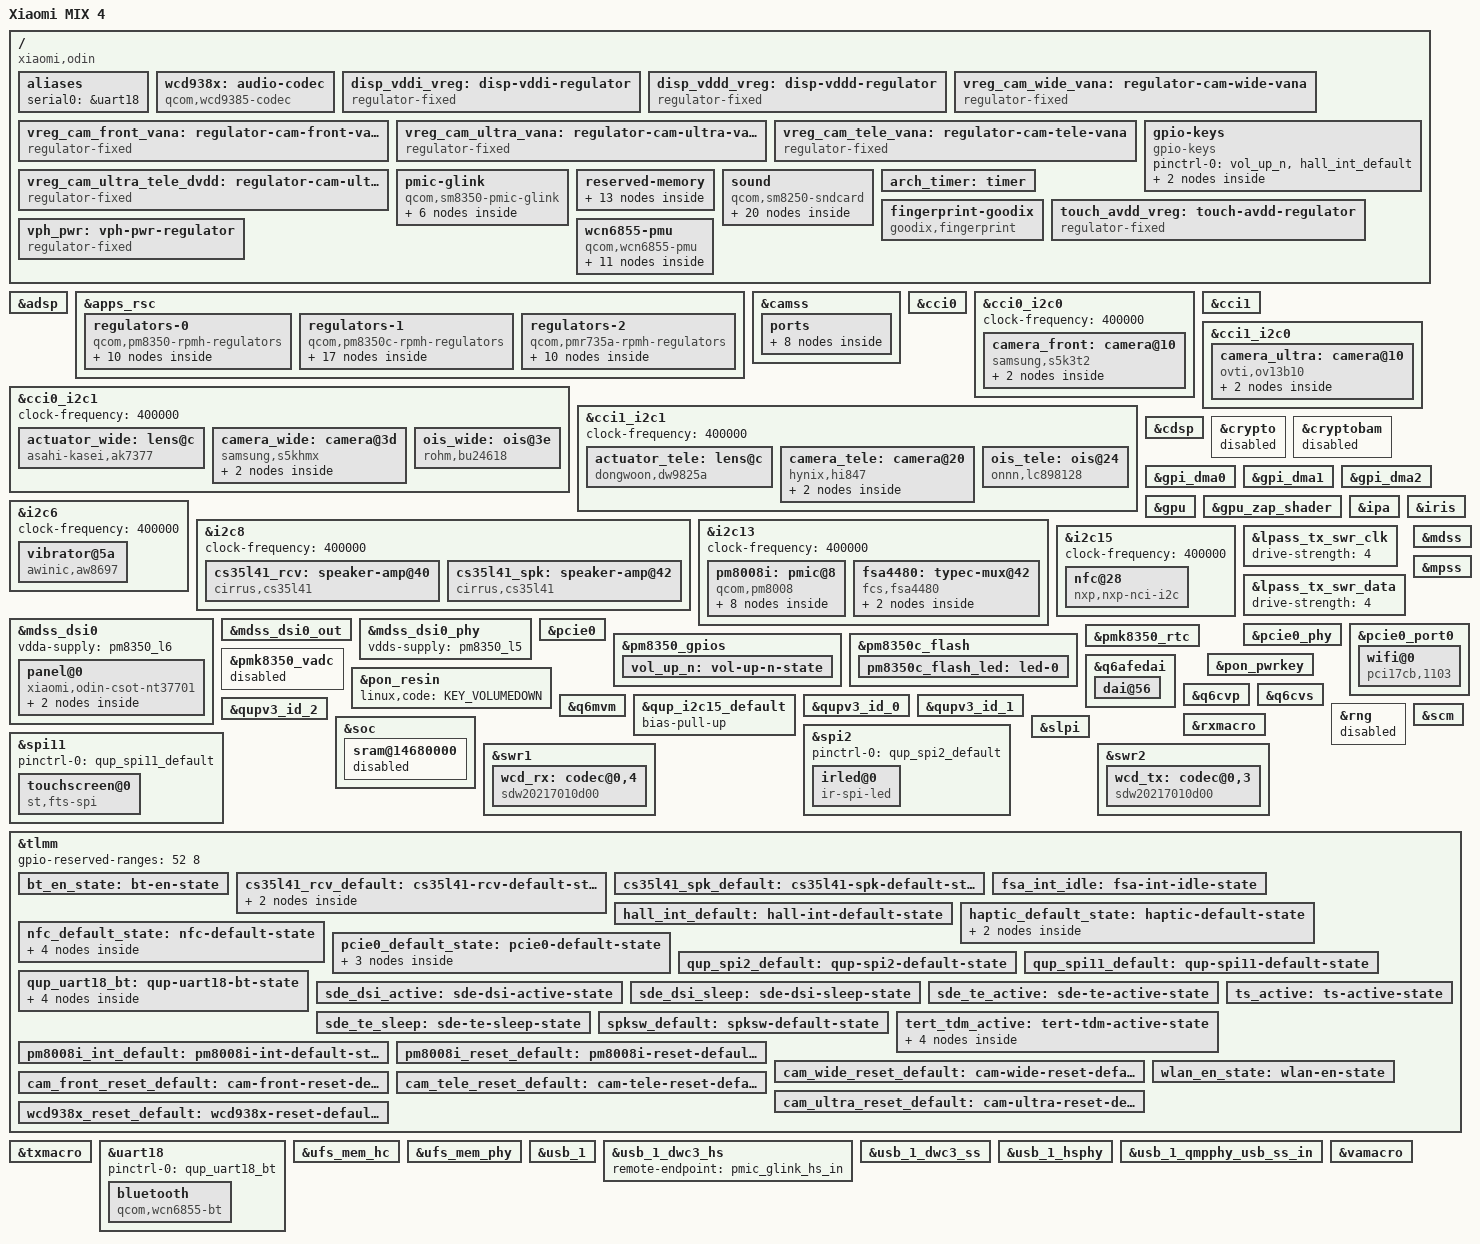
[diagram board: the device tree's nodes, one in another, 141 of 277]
// SPDX-License-Identifier: BSD-3-Clause

/dts-v1/;

#include <dt-bindings/clock/qcom,rpmh.h>
#include <dt-bindings/firmware/qcom,scm.h>
#include <dt-bindings/gpio/gpio.h>
#include <dt-bindings/input/input.h>
#include <dt-bindings/interconnect/qcom,icc.h>
#include <dt-bindings/interconnect/qcom,sm8350.h>
#include <dt-bindings/leds/common.h>
#include <dt-bindings/media/video-interfaces.h>
#include <dt-bindings/pinctrl/qcom,pmic-gpio.h>
#include <dt-bindings/power/qcom,rpmhpd.h>
#include <dt-bindings/regulator/qcom,rpmh-regulator.h>
#include <dt-bindings/sound/qcom,q6afe.h>
#include <dt-bindings/sound/qcom,q6asm.h>
#include <dt-bindings/sound/qcom,q6voice.h>
#include "sm8350.dtsi"
#include "pm8350.dtsi"
#include "pm8350b.dtsi"
#include "pm8350c.dtsi"
#include "pmk8350.dtsi"
#include "pmr735a.dtsi"

/delete-node/ &xbl_aop_mem;
/delete-node/ &pil_adsp_mem;
/delete-node/ &pil_slpi_mem;
/delete-node/ &pil_cdsp_mem;
/delete-node/ &pil_ipa_fw_mem;
/delete-node/ &pil_ipa_gsi_mem;
/delete-node/ &pil_gpu_mem;
/delete-node/ &pil_spss_mem;
/delete-node/ &pil_modem_mem;
/delete-node/ &rmtfs_mem;
/delete-node/ &hyp_reserved_mem;
/delete-node/ &pil_trustedvm_mem;
/delete-node/ &qrtr_shbuf;
/delete-node/ &chan0_shbuf;
/delete-node/ &chan1_shbuf;
/delete-node/ &removed_mem;

/ {
	model = "Xiaomi MIX 4";
	compatible = "xiaomi,odin", "qcom,sm8350";
	chassis-type = "handset";

	qcom,msm-id = <0x19f 0x20001 0x1c8 0x20001 0x1f5 0x20001>;
	qcom,board-id = <0 0>;

	aliases {
		serial0 = &uart18;
	};

	wcd938x: audio-codec {
		compatible = "qcom,wcd9385-codec";
		pinctrl-names = "default";
		pinctrl-0 = <&wcd938x_reset_default>;
		reset-gpios = <&tlmm 88 GPIO_ACTIVE_LOW>;

		vdd-rxtx-supply = <&pm8350_s10>;
		vdd-io-supply = <&pm8350_s10>;
		vdd-buck-supply = <&pm8350_s10>;
		vdd-mic-bias-supply = <&vreg_bob>;

		qcom,micbias1-microvolt = <2750000>;
		qcom,micbias2-microvolt = <2750000>;
		qcom,micbias3-microvolt = <2750000>;
		qcom,micbias4-microvolt = <2750000>;

		qcom,hphl-jack-type-normally-closed;
		qcom,ground-jack-type-normally-closed;
		qcom,mbhc-buttons-vthreshold-microvolt = <75000 150000 237000 500000
							  500000 500000 500000 500000>;
		qcom,mbhc-headset-vthreshold-microvolt = <1700000>;
		qcom,mbhc-headphone-vthreshold-microvolt = <50000>;

		qcom,rx-device = <&wcd_rx>;
		qcom,tx-device = <&wcd_tx>;

		#sound-dai-cells = <1>;
	};

	disp_vddi_vreg: disp-vddi-regulator {
		compatible = "regulator-fixed";
		regulator-name = "display_prim_vddi";
		gpio = <&tlmm 42 GPIO_ACTIVE_HIGH>;
		startup-delay-us = <2000>;
		enable-active-high;
		regulator-boot-on;
	};

	disp_vddd_vreg: disp-vddd-regulator {
		compatible = "regulator-fixed";
		regulator-name = "display_prim_vddd";
		gpio = <&tlmm 83 GPIO_ACTIVE_HIGH>;
		startup-delay-us = <2000>;
		enable-active-high;
		regulator-boot-on;
	};

	vreg_cam_wide_vana: regulator-cam-wide-vana {
		compatible = "regulator-fixed";
		regulator-name = "vreg_cam_wide_vana";
		regulator-min-microvolt = <2800000>;
		regulator-max-microvolt = <2800000>;
		startup-delay-us = <135>;
		off-on-delay-us = <20000>;
		enable-active-high;
		gpio = <&tlmm 6 GPIO_ACTIVE_HIGH>;
		vin-supply = <&vreg_bob>;
	};

	vreg_cam_front_vana: regulator-cam-front-vana {
		compatible = "regulator-fixed";
		regulator-name = "vreg_cam_front_vana";
		regulator-min-microvolt = <2800000>;
		regulator-max-microvolt = <2800000>;
		startup-delay-us = <135>;
		off-on-delay-us = <20000>;
		enable-active-high;
		gpio = <&tlmm 93 GPIO_ACTIVE_HIGH>;
		vin-supply = <&vreg_bob>;
	};

	vreg_cam_ultra_vana: regulator-cam-ultra-vana {
		compatible = "regulator-fixed";
		regulator-name = "vreg_cam_ultra_vana";
		regulator-min-microvolt = <2800000>;
		regulator-max-microvolt = <2800000>;
		startup-delay-us = <135>;
		off-on-delay-us = <20000>;
		enable-active-high;
		gpio = <&tlmm 66 GPIO_ACTIVE_HIGH>;
		vin-supply = <&vreg_bob>;
	};

	vreg_cam_tele_vana: regulator-cam-tele-vana {
		compatible = "regulator-fixed";
		regulator-name = "vreg_cam_tele_vana";
		regulator-min-microvolt = <2800000>;
		regulator-max-microvolt = <2800000>;
		startup-delay-us = <135>;
		off-on-delay-us = <20000>;
		enable-active-high;
		gpio = <&tlmm 34 GPIO_ACTIVE_HIGH>;
		vin-supply = <&vreg_bob>;
	};

	vreg_cam_ultra_tele_dvdd: regulator-cam-ultra-tele-dvdd {
		compatible = "regulator-fixed";
		regulator-name = "vreg_cam_ultra_tele_dvdd";
		regulator-min-microvolt = <1200000>;
		regulator-max-microvolt = <1200000>;
		startup-delay-us = <135>;
		off-on-delay-us = <20000>;
		enable-active-high;
		gpio = <&tlmm 74 GPIO_ACTIVE_HIGH>;
	};

	gpio-keys {
		compatible = "gpio-keys";

		pinctrl-names = "default";
		pinctrl-0 = <&vol_up_n &hall_int_default>;

		key-vol-up {
			label = "Volume Up";
			linux,code = <KEY_VOLUMEUP>;
			gpios = <&pm8350_gpios 6 GPIO_ACTIVE_LOW>;
			debounce-interval = <15>;
			linux,can-disable;
			wakeup-source;
		};

		switch-hall {
			label = "Hall Sensor";
			linux,input-type = <EV_SW>;
			linux,code = <SW_LID>;
			gpios = <&tlmm 80 GPIO_ACTIVE_LOW>;
			debounce-interval = <15>;
			wakeup-source;
		};
	};

	pmic-glink {
		compatible = "qcom,sm8350-pmic-glink", "qcom,pmic-glink";
		#address-cells = <1>;
		#size-cells = <0>;

		connector@0 {
			compatible = "usb-c-connector";
			reg = <0>;
			power-role = "dual";
			data-role = "dual";

			ports {
				#address-cells = <1>;
				#size-cells = <0>;

				port@0 {
					reg = <0>;

					pmic_glink_hs_in: endpoint {
						remote-endpoint = <&usb_1_dwc3_hs>;
					};
				};

				port@2 {
					reg = <2>;

					pmic_glink_sbu: endpoint {
						remote-endpoint = <&fsa4480_sbu_mux>;
					};
				};
			};
		};
	};

	reserved-memory {
		xbl_aop_mem: memory@80600000 {
			reg = <0x0 0x80600000 0x0 0x260000>;
			no-map;
		};

		pil_adsp_mem: memory@86100000 {
			reg = <0x0 0x86100000 0x0 0x3900000>;
			no-map;
		};

		pil_slpi_mem: memory@89a00000 {
			reg = <0x0 0x89a00000 0x0 0x2f00000>;
			no-map;
		};

		pil_cdsp_mem: memory@8c900000 {
			reg = <0x0 0x8c900000 0x0 0x1e00000>;
			no-map;
		};

		pil_ipa_fw_mem: memory@8e700000 {
			reg = <0x0 0x8e700000 0x0 0x10000>;
			no-map;
		};

		pil_ipa_gsi_mem: memory@8e710000 {
			reg = <0x0 0x8e710000 0x0 0xa000>;
			no-map;
		};

		pil_gpu_mem: memory@8e71a000 {
			reg = <0x0 0x8e71a000 0x0 0x2000>;
			no-map;
		};

		pil_spss_mem: memory@8e800000 {
			reg = <0x0 0x8e800000 0x0 0x100000>;
			no-map;
		};

		pil_modem_mem: memory@8f000000 {
			reg = <0x0 0x8f000000 0x0 0x10000000>;
			no-map;
		};

		rmtfs_mem: memory@9f000000 {
			compatible = "qcom,rmtfs-mem";
			reg = <0x0 0x9f000000 0x0 0x300000>;
			no-map;

			qcom,client-id = <1>;
			qcom,vmid = <QCOM_SCM_VMID_MSS_MSA>;
		};

		removed_mem: memory@d8800000 {
			reg = <0x0 0xd8800000 0x0 0xa000000>;
			no-map;
		};

		cont_splash_mem: memory@ea600000 {
			reg = <0x0 0xea600000 0x0 0x2300000>;
			no-map;
		};

		dfps_data_mem: memory@ec900000 {
			reg = <0x0 0xec900000 0x0 0x100000>;
			no-map;
		};
	};

	sound {
		compatible = "qcom,sm8250-sndcard";
		model = "Xiaomi MIX 4";
		pinctrl-names = "default";
		pinctrl-0 = <&tert_tdm_active &spksw_default>;

		audio-routing =
			"IN1_HPHL", "HPHL_OUT",
			"IN2_HPHR", "HPHR_OUT",
			"AMIC1", "MIC BIAS1",
			"AMIC2", "MIC BIAS2",
			"AMIC3", "MIC BIAS3",
			"AMIC5", "MIC BIAS4",
			"TX SWR_INPUT0", "ADC1_OUTPUT",
			"TX SWR_INPUT1", "ADC2_OUTPUT",
			"TX SWR_INPUT4", "ADC3_OUTPUT",
			"TX SWR_INPUT5", "ADC4_OUTPUT";

		mm1-dai-link {
			link-name = "MultiMedia1";

			cpu {
				sound-dai = <&q6asmdai MSM_FRONTEND_DAI_MULTIMEDIA1>;
			};
		};

		mm2-dai-link {
			link-name = "MultiMedia2";

			cpu {
				sound-dai = <&q6asmdai MSM_FRONTEND_DAI_MULTIMEDIA2>;
			};
		};

		mm3-dai-link {
			link-name = "MultiMedia3";

			cpu {
				sound-dai = <&q6asmdai MSM_FRONTEND_DAI_MULTIMEDIA3>;
			};
		};

		voicemmode1-dai-link {
			link-name = "VoiceMMode1";

			cpu {
				sound-dai = <&q6voicedai VOICEMMODE1>;
			};
		};

		speaker-dai-link {
			link-name = "Tertiary TDM Playback";

			cpu {
				sound-dai = <&q6afedai TERTIARY_TDM_RX_0>;
			};

			platform {
				sound-dai = <&q6routing>;
			};

			codec {
				sound-dai = <&cs35l41_rcv 0>, <&cs35l41_spk 0>;
			};
		};

		wcd-playback-dai-link {
			link-name = "WCD Playback";

			cpu {
				sound-dai = <&q6afedai RX_CODEC_DMA_RX_0>;
			};

			platform {
				sound-dai = <&q6routing>;
			};

			codec {
				sound-dai = <&wcd938x 0>, <&swr1 0>, <&rxmacro 0>;
			};
		};

		wcd-capture-dai-link {
			link-name = "WCD Capture";

			cpu {
				sound-dai = <&q6afedai TX_CODEC_DMA_TX_3>;
			};

			platform {
				sound-dai = <&q6routing>;
			};

			codec {
				sound-dai = <&wcd938x 1>, <&swr2 0>, <&txmacro 0>;
			};
		};
	};

	/* The arch_timer label is required by Gunyah/ABL to apply HypOverlay */
	arch_timer: timer { };

	fingerprint-goodix {
		compatible = "goodix,fingerprint";
		l11c-vdd-supply = <&pm8350c_l11>;
		reset-gpios = <&tlmm 39 GPIO_ACTIVE_LOW>;
		irq-gpios = <&tlmm 38 GPIO_ACTIVE_HIGH>;
	};

	touch_avdd_vreg: touch-avdd-regulator {
		compatible = "regulator-fixed";
		regulator-name = "touch_avdd";
		gpio = <&tlmm 132 GPIO_ACTIVE_HIGH>;
		enable-active-high;
	};

	vph_pwr: vph-pwr-regulator {
		compatible = "regulator-fixed";
		regulator-name = "vph_pwr";
		regulator-min-microvolt = <3700000>;
		regulator-max-microvolt = <3700000>;

		regulator-always-on;
		regulator-boot-on;
	};

	wcn6855-pmu {
		compatible = "qcom,wcn6855-pmu";

		pinctrl-names = "default";
		pinctrl-0 = <&bt_en_state>, <&wlan_en_state>;

		wlan-enable-gpios = <&tlmm 64 GPIO_ACTIVE_HIGH>;
		bt-enable-gpios = <&tlmm 65 GPIO_ACTIVE_HIGH>;
		swctrl-gpios = <&tlmm 153 GPIO_ACTIVE_HIGH>;

		vddio-supply = <&pm8350_s10>;
		vddaon-supply = <&pm8350_s11>;
		vddpmu-supply = <&pm8350_s12>;
		vddpmumx-supply = <&pmr735a_s2>;
		vddpmucx-supply = <&pm8350_s11>;
		vddrfa0p95-supply = <&pm8350_s11>;
		vddrfa1p3-supply = <&pm8350_s12>;
		vddrfa1p9-supply = <&pm8350c_s1>;
		vddpcie1p3-supply = <&pm8350_s12>;
		vddpcie1p9-supply = <&pm8350c_s1>;

		regulators {
			vreg_pmu_rfa_cmn: ldo0 {
				regulator-name = "vreg_pmu_rfa_cmn";
			};

			vreg_pmu_aon_0p8: ldo1 {
				regulator-name = "vreg_pmu_aon_0p8";
			};

			vreg_pmu_wlcx_0p8: ldo2 {
				regulator-name = "vreg_pmu_wlcx_0p8";
			};

			vreg_pmu_wlmx_0p8: ldo3 {
				regulator-name = "vreg_pmu_wlmx_0p8";
			};

			vreg_pmu_btcmx_0p8: ldo4 {
				regulator-name = "vreg_pmu_btcmx_0p8";
			};

			vreg_pmu_pcie_1p8: ldo5 {
				regulator-name = "vreg_pmu_pcie_1p8";
			};

			vreg_pmu_pcie_0p9: ldo6 {
				regulator-name = "vreg_pmu_pcie_0p9";
			};

			vreg_pmu_rfa_0p8: ldo7 {
				regulator-name = "vreg_pmu_rfa_0p8";
			};

			vreg_pmu_rfa_1p2: ldo8 {
				regulator-name = "vreg_pmu_rfa_1p2";
			};

			vreg_pmu_rfa_1p7: ldo9 {
				regulator-name = "vreg_pmu_rfa_1p7";
			};
		};
	};
};

&adsp {
	firmware-name = "qcom/sm8350/xiaomi/odin/adsp.mbn";
	status = "okay";
};

&apps_rsc {
	regulators-0 {
		compatible = "qcom,pm8350-rpmh-regulators";
		qcom,pmic-id = "b";

		vdd-s1-supply = <&vph_pwr>;
		vdd-s2-supply = <&vph_pwr>;
		vdd-s3-supply = <&vph_pwr>;
		vdd-s4-supply = <&vph_pwr>;
		vdd-s5-supply = <&vph_pwr>;
		vdd-s6-supply = <&vph_pwr>;
		vdd-s7-supply = <&vph_pwr>;
		vdd-s8-supply = <&vph_pwr>;
		vdd-s9-supply = <&vph_pwr>;
		vdd-s10-supply = <&vph_pwr>;
		vdd-s11-supply = <&vph_pwr>;
		vdd-s12-supply = <&vph_pwr>;

		vdd-l1-l4-supply = <&pm8350_s11>;
		vdd-l2-l7-supply = <&vreg_bob>;
		vdd-l3-l5-supply = <&pm8350_s11>;
		vdd-l6-l9-l10-supply = <&pm8350_s12>;

		pm8350_s10: smps10 {
			regulator-name = "pm8350_s10";
			regulator-min-microvolt = <1800000>;
			regulator-max-microvolt = <1800000>;
			regulator-initial-mode = <RPMH_REGULATOR_MODE_HPM>;
		};

		pm8350_s11: smps11 {
			regulator-name = "pm8350_s11";
			regulator-min-microvolt = <1008000>;
			regulator-max-microvolt = <1008000>;
			regulator-initial-mode = <RPMH_REGULATOR_MODE_HPM>;
		};

		pm8350_s12: smps12 {
			regulator-name = "pm8350_s12";
			regulator-min-microvolt = <1352000>;
			regulator-max-microvolt = <1352000>;
			regulator-initial-mode = <RPMH_REGULATOR_MODE_HPM>;
		};

		pm8350_l1: ldo1 {
			regulator-name = "pm8350_l1";
			regulator-min-microvolt = <912000>;
			regulator-max-microvolt = <920000>;
			regulator-initial-mode = <RPMH_REGULATOR_MODE_HPM>;
		};

		pm8350_l2: ldo2 {
			regulator-name = "pm8350_l2";
			regulator-min-microvolt = <3072000>;
			regulator-max-microvolt = <3072000>;
			regulator-initial-mode = <RPMH_REGULATOR_MODE_HPM>;
		};

		pm8350_l3: ldo3 {
			regulator-name = "pm8350_l3";
			regulator-min-microvolt = <904000>;
			regulator-max-microvolt = <904000>;
			regulator-initial-mode = <RPMH_REGULATOR_MODE_HPM>;
		};

		pm8350_l5: ldo5 {
			regulator-name = "pm8350_l5";
			regulator-min-microvolt = <880000>;
			regulator-max-microvolt = <888000>;
			regulator-initial-mode = <RPMH_REGULATOR_MODE_HPM>;
			regulator-allow-set-load;
			regulator-allowed-modes = <RPMH_REGULATOR_MODE_HPM>;
		};

		pm8350_l6: ldo6 {
			regulator-name = "pm8350_l6";
			regulator-min-microvolt = <1200000>;
			regulator-max-microvolt = <1208000>;
			regulator-initial-mode = <RPMH_REGULATOR_MODE_HPM>;
			regulator-allow-set-load;
			regulator-allowed-modes = <RPMH_REGULATOR_MODE_HPM>;
		};

		pm8350_l7: ldo7 {
			regulator-name = "pm8350_l7";
			regulator-min-microvolt = <2400000>;
			regulator-max-microvolt = <3008000>;
			regulator-initial-mode = <RPMH_REGULATOR_MODE_HPM>;
			regulator-allow-set-load;
			regulator-allowed-modes = <RPMH_REGULATOR_MODE_LPM
						   RPMH_REGULATOR_MODE_HPM>;
		};

		pm8350_l9: ldo9 {
			regulator-name = "pm8350_l9";
			regulator-min-microvolt = <1200000>;
			regulator-max-microvolt = <1200000>;
			regulator-initial-mode = <RPMH_REGULATOR_MODE_HPM>;
			regulator-allow-set-load;
			regulator-allowed-modes = <RPMH_REGULATOR_MODE_LPM
						   RPMH_REGULATOR_MODE_HPM>;
		};
	};

	regulators-1 {
		compatible = "qcom,pm8350c-rpmh-regulators";
		qcom,pmic-id = "c";

		vdd-s1-supply = <&vph_pwr>;
		vdd-s2-supply = <&vph_pwr>;
		vdd-s3-supply = <&vph_pwr>;
		vdd-s4-supply = <&vph_pwr>;
		vdd-s5-supply = <&vph_pwr>;
		vdd-s6-supply = <&vph_pwr>;
		vdd-s7-supply = <&vph_pwr>;
		vdd-s8-supply = <&vph_pwr>;
		vdd-s9-supply = <&vph_pwr>;
		vdd-s10-supply = <&vph_pwr>;

		vdd-l1-l12-supply = <&pm8350c_s1>;
		vdd-l2-l8-supply = <&pm8350c_s1>;
		vdd-l3-l4-l5-l7-l13-supply = <&vreg_bob>;
		vdd-l6-l9-l11-supply = <&vreg_bob>;
		vdd-l10-supply = <&pm8350_s12>;

		vdd-bob-supply = <&vph_pwr>;

		pm8350c_s1: smps1 {
			regulator-name = "pm8350c_s1";
			regulator-min-microvolt = <1904000>;
			regulator-max-microvolt = <1904000>;
			regulator-initial-mode = <RPMH_REGULATOR_MODE_HPM>;
		};

		pm8350c_s3: smps3 {
			regulator-name = "pm8350c_s3";
			regulator-min-microvolt = <300000>;
			regulator-max-microvolt = <704000>;
			regulator-initial-mode = <RPMH_REGULATOR_MODE_HPM>;
		};

		pm8350c_s10: smps10 {
			regulator-name = "pm8350c_s10";
			regulator-min-microvolt = <1048000>;
			regulator-max-microvolt = <1128000>;
			regulator-initial-mode = <RPMH_REGULATOR_MODE_HPM>;
		};

		pm8350c_l1: ldo1 {
			regulator-name = "pm8350c_l1";
			regulator-min-microvolt = <1800000>;
			regulator-max-microvolt = <1800000>;
			regulator-initial-mode = <RPMH_REGULATOR_MODE_HPM>;
		};

		pm8350c_l2: ldo2 {
			regulator-name = "pm8350c_l2";
			regulator-min-microvolt = <1800000>;
			regulator-max-microvolt = <1800000>;
			regulator-initial-mode = <RPMH_REGULATOR_MODE_HPM>;
		};

		pm8350c_l3: ldo3 {
			regulator-name = "pm8350c_l3";
			regulator-min-microvolt = <3008000>;
			regulator-max-microvolt = <3008000>;
			regulator-initial-mode = <RPMH_REGULATOR_MODE_HPM>;
		};

		pm8350c_l4: ldo4 {
			regulator-name = "pm8350c_l4";
			regulator-min-microvolt = <1704000>;
			regulator-max-microvolt = <3000000>;
			regulator-initial-mode = <RPMH_REGULATOR_MODE_HPM>;
		};

		pm8350c_l5: ldo5 {
			regulator-name = "pm8350c_l5";
			regulator-min-microvolt = <1704000>;
			regulator-max-microvolt = <3000000>;
			regulator-initial-mode = <RPMH_REGULATOR_MODE_HPM>;
		};

		pm8350c_l6: ldo6 {
			regulator-name = "pm8350c_l6";
			regulator-min-microvolt = <1800000>;
			regulator-max-microvolt = <2960000>;
			regulator-initial-mode = <RPMH_REGULATOR_MODE_HPM>;
		};

		pm8350c_l7: ldo7 {
			regulator-name = "pm8350c_l7";
			regulator-min-microvolt = <3008000>;
			regulator-max-microvolt = <3008000>;
			regulator-initial-mode = <RPMH_REGULATOR_MODE_HPM>;
		};

		pm8350c_l8: ldo8 {
			regulator-name = "pm8350c_l8";
			regulator-min-microvolt = <1800000>;
			regulator-max-microvolt = <1800000>;
			regulator-initial-mode = <RPMH_REGULATOR_MODE_HPM>;
		};

		pm8350c_l9: ldo9 {
			regulator-name = "pm8350c_l9";
			regulator-min-microvolt = <2960000>;
			regulator-max-microvolt = <3008000>;
			regulator-initial-mode = <RPMH_REGULATOR_MODE_HPM>;
		};

		pm8350c_l10: ldo10 {
			regulator-name = "pm8350c_l10";
			regulator-min-microvolt = <1200000>;
			regulator-max-microvolt = <1200000>;
			regulator-initial-mode = <RPMH_REGULATOR_MODE_HPM>;
		};

		pm8350c_l11: ldo11 {
			regulator-name = "pm8350c_l11";
			regulator-min-microvolt = <3008000>;
			regulator-max-microvolt = <3008000>;
			regulator-initial-mode = <RPMH_REGULATOR_MODE_HPM>;
			regulator-boot-on;
			regulator-always-on;
		};

		pm8350c_l12: ldo12 {
			regulator-name = "pm8350c_l12";
			regulator-min-microvolt = <1800000>;
			regulator-max-microvolt = <2000000>;
			regulator-initial-mode = <RPMH_REGULATOR_MODE_HPM>;
			regulator-boot-on;
			regulator-always-on;
		};

		pm8350c_l13: ldo13 {
			regulator-name = "pm8350c_l13";
			regulator-min-microvolt = <3000000>;
			regulator-max-microvolt = <3000000>;
			regulator-initial-mode = <RPMH_REGULATOR_MODE_HPM>;
			regulator-allow-set-load;
			regulator-allowed-modes = <RPMH_REGULATOR_MODE_LPM
						   RPMH_REGULATOR_MODE_HPM>;
			regulator-boot-on;
		};

		vreg_bob: bob {
			regulator-name = "vreg_bob";
			regulator-min-microvolt = <3296000>;
			regulator-max-microvolt = <3960000>;
			regulator-initial-mode = <RPMH_REGULATOR_MODE_AUTO>;
		};
	};

	regulators-2 {
		compatible = "qcom,pmr735a-rpmh-regulators";
		qcom,pmic-id = "e";

		vdd-s1-supply = <&vph_pwr>;
		vdd-s2-supply = <&vph_pwr>;
		vdd-s3-supply = <&vph_pwr>;

		vdd-l1-l2-supply = <&pmr735a_s2>;
		vdd-l3-supply = <&pmr735a_s1>;
		vdd-l4-supply = <&pm8350c_s1>;
		vdd-l5-l6-supply = <&pm8350c_s1>;
		vdd-l7-bob-supply = <&vreg_bob>;

		pmr735a_s1: smps1 {
			regulator-name = "pmr735a_s1";
			regulator-min-microvolt = <1200000>;
			regulator-max-microvolt = <1280000>;
		};

		pmr735a_s2: smps2 {
			regulator-name = "pmr735a_s2";
			regulator-min-microvolt = <1012000>;
			regulator-max-microvolt = <1012000>;
		};

		pmr735a_s3: smps3 {
			regulator-name = "pmr735a_s3";
			regulator-min-microvolt = <2200000>;
			regulator-max-microvolt = <2352000>;
		};

		pmr735a_l1: ldo1 {
			regulator-name = "pmr735a_l1";
			regulator-min-microvolt = <912000>;
			regulator-max-microvolt = <912000>;
		};

		pmr735a_l2: ldo2 {
			regulator-name = "pmr735a_l2";
			regulator-min-microvolt = <1200000>;
			regulator-max-microvolt = <1200000>;
		};

		pmr735a_l3: ldo3 {
			regulator-name = "pmr735a_l3";
			regulator-min-microvolt = <1200000>;
			regulator-max-microvolt = <1200000>;
		};

		pmr735a_l4: ldo4 {
			regulator-name = "pmr735a_l4";
			regulator-min-microvolt = <1776000>;
			regulator-max-microvolt = <1872000>;
		};

		pmr735a_l5: ldo5 {
			regulator-name = "pmr735a_l5";
			regulator-min-microvolt = <800000>;
			regulator-max-microvolt = <800000>;
		};

		pmr735a_l6: ldo6 {
			regulator-name = "pmr735a_l6";
			regulator-min-microvolt = <480000>;
			regulator-max-microvolt = <904000>;
		};

		/* 2.8V WLAN/BT RF antenna switch diversity */
		pmr735a_l7: ldo7 {
			regulator-name = "pmr735a_l7";
			regulator-min-microvolt = <2800000>;
			regulator-max-microvolt = <2800000>;
			regulator-boot-on;
			regulator-always-on;
		};
	};
};

&camss {
	vdda-phy-supply = <&pm8350_l5>;
	vdda-pll-supply = <&pm8350_l6>;
	status = "okay";

	ports {
		port@1 {
			csiphy1_ep: endpoint {
				data-lanes = <0 1 2>;
				bus-type = <MEDIA_BUS_TYPE_CSI2_CPHY>;
				remote-endpoint = <&s5khmx_wide_ep>;
			};
		};

		port@3 {
			csiphy3_ep: endpoint {
				clock-lanes = <7>;
				data-lanes = <0 1 2 3>;
				bus-type = <MEDIA_BUS_TYPE_CSI2_DPHY>;
				remote-endpoint = <&ov13b10_ultra_ep>;
			};
		};

		port@4 {
			csiphy4_ep: endpoint {
				clock-lanes = <7>;
				data-lanes = <0 1>;
				bus-type = <MEDIA_BUS_TYPE_CSI2_DPHY>;
				remote-endpoint = <&hi847_tele_ep>;
			};
		};

		port@5 {
			csiphy5_ep: endpoint {
				clock-lanes = <7>;
				data-lanes = <0 1 2 3>;
				bus-type = <MEDIA_BUS_TYPE_CSI2_DPHY>;
				remote-endpoint = <&s5k3t2_front_ep>;
			};
		};
	};
};

&cci0 {
	status = "okay";
};

&cci0_i2c0 {
	clock-frequency = <400000>;

	camera_front: camera@10 {
		compatible = "samsung,s5k3t2";
		reg = <0x10>;

		reset-gpios = <&tlmm 17 GPIO_ACTIVE_LOW>;
		pinctrl-names = "default";
		pinctrl-0 = <&cam_mclk1_default>, <&cam_front_reset_default>;

		clocks = <&camcc CAM_CC_MCLK1_CLK>;
		assigned-clocks = <&camcc CAM_CC_MCLK1_CLK>;
		assigned-clock-rates = <19200000>;
		power-domains = <&camcc TITAN_TOP_GDSC>;

		vddio-supply = <&pm8008i_l6>;
		vdda-supply = <&vreg_cam_front_vana>;
		vddd-supply = <&pm8008i_l1>;

		orientation = <0>;
		rotation = <90>;

		port {
			s5k3t2_front_ep: endpoint {
				data-lanes = <1 2 3 4>;
				link-frequencies = /bits/ 64 <310400000>;
				remote-endpoint = <&csiphy5_ep>;
			};
		};
	};
};

&cci0_i2c1 {
	clock-frequency = <400000>;

	actuator_wide: lens@c {
		compatible = "asahi-kasei,ak7377";
		reg = <0x0c>;

		vdd-supply = <&pm8008i_l4>;
		vio-supply = <&pm8008i_l6>;
	};

	camera_wide: camera@3d {
		compatible = "samsung,s5khmx";
		reg = <0x3d>;

		reset-gpios = <&tlmm 16 GPIO_ACTIVE_LOW>;
		pinctrl-names = "default";
		pinctrl-0 = <&cam_mclk3_default>, <&cam_wide_reset_default>;

		clocks = <&camcc CAM_CC_MCLK3_CLK>;
		assigned-clocks = <&camcc CAM_CC_MCLK3_CLK>;
		assigned-clock-rates = <19200000>;
		power-domains = <&camcc TITAN_TOP_GDSC>;

		vddio-supply = <&pm8008i_l6>;
		vdda-supply = <&vreg_cam_wide_vana>;
		vddd-supply = <&pm8008i_l2>;

		lens-focus = <&actuator_wide>;
		lens-ois = <&ois_wide>;
		flash-leds = <&pm8350c_flash_led>;

		orientation = <1>;
		rotation = <270>;

		port {
			s5khmx_wide_ep: endpoint {
				bus-type = <MEDIA_BUS_TYPE_CSI2_CPHY>;
				data-lanes = <0 1 2>;
				link-frequencies = /bits/ 64 <601600000 1798400000>;
				remote-endpoint = <&csiphy1_ep>;
			};
		};
	};

	ois_wide: ois@3e {
		compatible = "rohm,bu24618";
		reg = <0x3e>;

		vdd-supply = <&pm8008i_l3>;
		vaf-supply = <&pm8008i_l4>;
		vio-supply = <&pm8008i_l6>;
		firmware-name = "qcom/sm8350/xiaomi/odin/odin_wide_bu24618_ois";
	};
};

&cci1 {
	status = "okay";
};

&cci1_i2c0 {
	camera_ultra: camera@10 {
		compatible = "ovti,ov13b10";
		reg = <0x10>;

		reset-gpios = <&tlmm 117 GPIO_ACTIVE_LOW>;
		pinctrl-names = "default";
		pinctrl-0 = <&cam_mclk2_default>, <&cam_ultra_reset_default>;

		clocks = <&camcc CAM_CC_MCLK2_CLK>;
		assigned-clocks = <&camcc CAM_CC_MCLK2_CLK>;
		assigned-clock-rates = <19200000>;
		power-domains = <&camcc TITAN_TOP_GDSC>;

		dovdd-supply = <&pm8008i_l6>;
		avdd-supply = <&vreg_cam_ultra_vana>;
		dvdd-supply = <&vreg_cam_ultra_tele_dvdd>;

		orientation = <1>;
		rotation = <270>;

		port {
			ov13b10_ultra_ep: endpoint {
				data-lanes = <1 2 3 4>;
				link-frequencies = /bits/ 64 <560000000>;
				remote-endpoint = <&csiphy3_ep>;
			};
		};
	};
};

&cci1_i2c1 {
	clock-frequency = <400000>;

	actuator_tele: lens@c {
		compatible = "dongwoon,dw9825a";
		reg = <0x0c>;

		vdd-supply = <&pm8008i_l7>;
		vio-supply = <&pm8008i_l6>;
	};

	camera_tele: camera@20 {
		compatible = "hynix,hi847";
		reg = <0x20>;

		reset-gpios = <&tlmm 106 GPIO_ACTIVE_LOW>;
		pinctrl-names = "default";
		pinctrl-0 = <&cam_mclk0_default>, <&cam_tele_reset_default>;

		clocks = <&camcc CAM_CC_MCLK0_CLK>;
		assigned-clocks = <&camcc CAM_CC_MCLK0_CLK>;
		assigned-clock-rates = <19200000>;
		power-domains = <&camcc TITAN_TOP_GDSC>;

		vddio-supply = <&pm8008i_l6>;
		vdda-supply = <&vreg_cam_tele_vana>;
		vddd-supply = <&vreg_cam_ultra_tele_dvdd>;

		lens-focus = <&actuator_tele>;
		lens-ois = <&ois_tele>;

		orientation = <1>;
		rotation = <270>;

		port {
			hi847_tele_ep: endpoint {
				data-lanes = <1 2>;
				link-frequencies = /bits/ 64 <840000000 400000000>;
				remote-endpoint = <&csiphy4_ep>;
			};
		};
	};

	ois_tele: ois@24 {
		compatible = "onnn,lc898128";
		reg = <0x24>;

		vdd-supply = <&pm8008i_l7>;
		vio-supply = <&pm8008i_l6>;
	};
};

&cdsp {
	firmware-name = "qcom/sm8350/xiaomi/odin/cdsp.mbn";
	status = "okay";
};

&crypto {
	status = "disabled";
};

&cryptobam {
	status = "disabled";
};

&gpi_dma0 {
	status = "okay";
};

&gpi_dma1 {
	status = "okay";
};

&gpi_dma2 {
	status = "okay";
};

&gpu {
	status = "okay";
};

&gpu_zap_shader {
	firmware-name = "qcom/sm8350/xiaomi/odin/a660_zap.mbn";
};

&i2c6 {
	clock-frequency = <400000>;
	status = "okay";

	vibrator@5a {
		compatible = "awinic,aw8697";
		reg = <0x5a>;
		interrupts-extended = <&tlmm 119 IRQ_TYPE_EDGE_FALLING>;
		reset-gpios = <&tlmm 155 GPIO_ACTIVE_LOW>;
		pinctrl-names = "default";
		pinctrl-0 = <&haptic_default_state>;
	};
};

&i2c8 {
	clock-frequency = <400000>;
	status = "okay";

	cs35l41_rcv: speaker-amp@40 {
		compatible = "cirrus,cs35l41";
		reg = <0x40>;
		interrupts-extended = <&tlmm 31 IRQ_TYPE_LEVEL_LOW>;
		reset-gpios = <&tlmm 78 GPIO_ACTIVE_HIGH>;
		VA-supply = <&pm8350_s10>;
		VP-supply = <&vph_pwr>;
		pinctrl-names = "default";
		pinctrl-0 = <&cs35l41_rcv_default>;
		sound-name-prefix = "RCV";
		cirrus,subsystem-id = "xiaomi-odin";
		cirrus,boost-type = <0>;
		cirrus,boost-peak-milliamp = <4000>;
		cirrus,boost-ind-nanohenry = <1000>;
		cirrus,boost-cap-microfarad = <15>;
		cirrus,asp-sdout-hiz = <3>;
		cirrus,gpio2-src-select = <4>;
		cirrus,gpio2-output-enable;
		#sound-dai-cells = <1>;
	};

	cs35l41_spk: speaker-amp@42 {
		compatible = "cirrus,cs35l41";
		reg = <0x42>;
		interrupts-extended = <&tlmm 116 IRQ_TYPE_LEVEL_LOW>;
		reset-gpios = <&tlmm 78 GPIO_ACTIVE_HIGH>;
		VA-supply = <&pm8350_s10>;
		VP-supply = <&vph_pwr>;
		pinctrl-names = "default";
		pinctrl-0 = <&cs35l41_spk_default>;
		sound-name-prefix = "SPK";
		cirrus,subsystem-id = "xiaomi-odin";
		cirrus,boost-type = <0>;
		cirrus,boost-peak-milliamp = <4000>;
		cirrus,boost-ind-nanohenry = <1000>;
		cirrus,boost-cap-microfarad = <15>;
		cirrus,asp-sdout-hiz = <3>;
		cirrus,gpio2-src-select = <4>;
		cirrus,gpio2-output-enable;
		#sound-dai-cells = <1>;
	};
};

&i2c13 {
	clock-frequency = <400000>;
	status = "okay";

	pm8008i: pmic@8 {
		compatible = "qcom,pm8008";
		reg = <0x8>;

		interrupts-extended = <&tlmm 32 IRQ_TYPE_EDGE_RISING>;
		reset-gpios = <&tlmm 33 GPIO_ACTIVE_LOW>;

		vdd-l1-l2-supply = <&pm8350_s12>;
		vdd-l3-l4-supply = <&vreg_bob>;
		vdd-l5-supply = <&pm8350c_s1>;
		vdd-l6-supply = <&pm8350c_s1>;
		vdd-l7-supply = <&vreg_bob>;

		pinctrl-names = "default";
		pinctrl-0 = <&pm8008i_int_default>, <&pm8008i_reset_default>;

		gpio-controller;
		#gpio-cells = <2>;
		gpio-ranges = <&pm8008i 0 0 2>;

		interrupt-controller;
		#interrupt-cells = <2>;

		#thermal-sensor-cells = <0>;

		regulators {
			pm8008i_l1: ldo1 {
				regulator-name = "pm8008i_l1";
				regulator-min-microvolt = <1056000>;
				regulator-max-microvolt = <1056000>;
			};

			pm8008i_l2: ldo2 {
				regulator-name = "pm8008i_l2";
				regulator-min-microvolt = <1104000>;
				regulator-max-microvolt = <1104000>;
			};

			pm8008i_l3: ldo3 {
				regulator-name = "pm8008i_l3";
				regulator-min-microvolt = <2800000>;
				regulator-max-microvolt = <2800000>;
			};

			pm8008i_l4: ldo4 {
				regulator-name = "pm8008i_l4";
				regulator-min-microvolt = <2696000>;
				regulator-max-microvolt = <2904000>;
			};

			pm8008i_l5: ldo5 {
				regulator-name = "pm8008i_l5";
				regulator-min-microvolt = <1696000>;
				regulator-max-microvolt = <1800000>;
			};

			pm8008i_l6: ldo6 {
				regulator-name = "pm8008i_l6";
				regulator-min-microvolt = <1800000>;
				regulator-max-microvolt = <1800000>;
			};

			pm8008i_l7: ldo7 {
				regulator-name = "pm8008i_l7";
				regulator-min-microvolt = <2856000>;
				regulator-max-microvolt = <3000000>;
			};
		};
	};

	fsa4480: typec-mux@42 {
		compatible = "fcs,fsa4480";
		reg = <0x42>;

		interrupts-extended = <&tlmm 2 IRQ_TYPE_LEVEL_LOW>;
		pinctrl-names = "default";
		pinctrl-0 = <&fsa_int_idle>;

		vcc-supply = <&vreg_bob>;

		mode-switch;
		orientation-switch;

		port {
			fsa4480_sbu_mux: endpoint {
				remote-endpoint = <&pmic_glink_sbu>;
			};
		};
	};
};

&i2c15 {
	clock-frequency = <400000>;
	status = "okay";

	nfc@28 {
		compatible = "nxp,nxp-nci-i2c";
		reg = <0x28>;

		interrupt-parent = <&tlmm>;
		interrupts = <87 IRQ_TYPE_EDGE_RISING>;

		enable-gpios = <&tlmm 62 GPIO_ACTIVE_HIGH>;
		firmware-gpios = <&tlmm 86 GPIO_ACTIVE_HIGH>;

		pinctrl-names = "default";
		pinctrl-0 = <&nfc_default_state>;
	};
};

&ipa {
	firmware-name = "qcom/sm8350/xiaomi/odin/ipa_fws.mbn";
	status = "okay";
};

&iris {
	firmware-name = "qcom/sm8350/xiaomi/odin/vpu20_4v.mbn";
	status = "okay";
};

&lpass_tx_swr_clk {
	drive-strength = <4>;
};

&lpass_tx_swr_data {
	drive-strength = <4>;
};

&mdss {
	status = "okay";
};

&mdss_dsi0 {
	vdda-supply = <&pm8350_l6>;
	status = "okay";

	panel@0 {
		compatible = "xiaomi,odin-csot-nt37701";
		reg = <0>;
		avdd-supply = <&pm8350c_l13>;
		vddd-supply = <&disp_vddd_vreg>;
		vddio-supply = <&disp_vddi_vreg>;
		reset-gpios = <&tlmm 24 GPIO_ACTIVE_LOW>;
		pinctrl-names = "default", "sleep";
		pinctrl-0 = <&sde_dsi_active &sde_te_active>;
		pinctrl-1 = <&sde_dsi_sleep &sde_te_sleep>;

		port {
			panel0_in: endpoint {
				remote-endpoint = <&mdss_dsi0_out>;
			};
		};
	};
};

&mdss_dsi0_out {
	remote-endpoint = <&panel0_in>;
	data-lanes = <0 1 2 3>;
};

&mdss_dsi0_phy {
	vdds-supply = <&pm8350_l5>;
	status = "okay";
};

&mpss {
	firmware-name = "qcom/sm8350/xiaomi/odin/modem.mbn";
	status = "okay";
};

&pcie0 {
	pinctrl-names = "default";
	pinctrl-0 = <&pcie0_default_state>;
	max-link-speed = <2>;
	status = "okay";
};

&pcie0_phy {
	vdda-phy-supply = <&pm8350_l5>;
	vdda-pll-supply = <&pm8350_l6>;
	status = "okay";
};

&pcie0_port0 {
	reset-gpios = <&tlmm 94 GPIO_ACTIVE_LOW>;
	wake-gpios = <&tlmm 96 GPIO_ACTIVE_LOW>;
	aspm-no-l0s;

	wifi@0 {
		compatible = "pci17cb,1103";
		reg = <0x10000 0x0 0x0 0x0 0x0>;

		vddrfacmn-supply = <&vreg_pmu_rfa_cmn>;
		vddaon-supply = <&vreg_pmu_aon_0p8>;
		vddwlcx-supply = <&vreg_pmu_wlcx_0p8>;
		vddwlmx-supply = <&vreg_pmu_wlmx_0p8>;
		vddpcie1p8-supply = <&vreg_pmu_pcie_1p8>;
		vddpcie0p9-supply = <&vreg_pmu_pcie_0p9>;
		vddrfa0p8-supply = <&vreg_pmu_rfa_0p8>;
		vddrfa1p2-supply = <&vreg_pmu_rfa_1p2>;
		vddrfa1p8-supply = <&vreg_pmu_rfa_1p7>;

		qcom,ath11k-calibration-variant = "Xiaomi_MIX4";
	};
};

&pm8350_gpios {
	vol_up_n: vol-up-n-state {
		pins = "gpio6";
		function = "normal";
		power-source = <1>;
		bias-pull-up;
		input-enable;
	};
};

&pm8350c_flash {
	status = "okay";

	pm8350c_flash_led: led-0 {
		function = LED_FUNCTION_FLASH;
		color = <LED_COLOR_ID_WHITE>;
		led-sources = <1>, <2>;
		led-max-microamp = <300000>;
		flash-max-microamp = <1500000>;
		flash-max-timeout-us = <1280000>;
	};
};

&pmk8350_rtc {
	status = "okay";
};

&pmk8350_vadc {
	status = "disabled";
};

&pon_pwrkey {
	status = "okay";
};

&pon_resin {
	linux,code = <KEY_VOLUMEDOWN>;
	status = "okay";
};

&q6afedai {
	dai@56 {
		reg = <TERTIARY_TDM_RX_0>;
		qcom,tdm-sync-mode = <0>;
		qcom,tdm-sync-src = <1>;
		qcom,tdm-data-out = <0>;
		qcom,tdm-invert-sync = <1>;
		qcom,tdm-data-delay = <1>;
		qcom,tdm-data-align = <0>;
	};
};

&q6cvp {
	status = "okay";
};

&q6cvs {
	status = "okay";
};

&q6mvm {
	status = "okay";
};

&qup_i2c15_default {
	/delete-property/ bias-disable;
	bias-pull-up;
};

&qupv3_id_0 {
	status = "okay";
};

&qupv3_id_1 {
	status = "okay";
};

&qupv3_id_2 {
	status = "okay";
};

&rng {
	status = "disabled";
};

&rxmacro {
	status = "okay";
};

&scm {
	/delete-property/ sram;
};

&slpi {
	firmware-name = "qcom/sm8350/xiaomi/odin/slpi.mbn";
	status = "okay";
};

&soc {
	/*
	 * 0x14680000..0x146befff is TZ/HYP XPU-protected OCIMEM on Odin;
	 * only 0x146bf000..0x146bffff is HLOS IMEM.
	 */
	sram@14680000 {
		status = "disabled";
	};
};

&spi2 {
	pinctrl-names = "default";
	pinctrl-0 = <&qup_spi2_default>;
	status = "okay";

	irled@0 {
		compatible = "ir-spi-led";
		reg = <0>;
		spi-max-frequency = <19200000>;
	};
};

&spi11 {
	pinctrl-names = "default";
	pinctrl-0 = <&qup_spi11_default>;
	status = "okay";

	touchscreen@0 {
		compatible = "st,fts-spi";
		reg = <0>;
		spi-max-frequency = <7000000>;
		interrupts-extended = <&tlmm 23 IRQ_TYPE_LEVEL_LOW>;
		reset-gpios = <&tlmm 22 GPIO_ACTIVE_LOW>;
		avdd-supply = <&touch_avdd_vreg>;
		vdd-supply = <&pm8350c_l2>;
		pinctrl-names = "default";
		pinctrl-0 = <&ts_active>;
		touchscreen-size-x = <10800>;
		touchscreen-size-y = <24000>;
		st,super-resolution;
	};
};

&swr1 {
	status = "okay";

	wcd_rx: codec@0,4 {
		compatible = "sdw20217010d00";
		reg = <0 4>;
		qcom,rx-port-mapping = <1 2 3 4 5>;
	};
};

&swr2 {
	status = "okay";

	wcd_tx: codec@0,3 {
		compatible = "sdw20217010d00";
		reg = <0 3>;
		qcom,tx-port-mapping = <1 2 3 4>;
	};
};

&tlmm {
	gpio-reserved-ranges = <52 8>;

	bt_en_state: bt-en-state {
		pins = "gpio65";
		function = "gpio";
		drive-strength = <16>;
		output-low;
		bias-pull-down;
	};

	cs35l41_rcv_default: cs35l41-rcv-default-state {
		int-pins {
			pins = "gpio31";
			function = "gpio";
			drive-strength = <2>;
			bias-pull-up;
		};

		rst-pins {
			pins = "gpio78";
			function = "gpio";
			drive-strength = <2>;
			bias-disable;
		};
	};

	cs35l41_spk_default: cs35l41-spk-default-state {
		pins = "gpio116";
		function = "gpio";
		drive-strength = <2>;
		bias-pull-up;
	};

	fsa_int_idle: fsa-int-idle-state {
		pins = "gpio2";
		function = "gpio";
		drive-strength = <2>;
		bias-disable;
	};

	hall_int_default: hall-int-default-state {
		pins = "gpio80";
		function = "gpio";
		drive-strength = <2>;
		bias-pull-up;
	};

	haptic_default_state: haptic-default-state {
		rst-pins {
			pins = "gpio155";
			function = "gpio";
			drive-strength = <2>;
			bias-pull-up;
		};

		int-pins {
			pins = "gpio119";
			function = "gpio";
			drive-strength = <2>;
			bias-pull-up;
		};
	};

	nfc_default_state: nfc-default-state {
		int-pins {
			pins = "gpio87";
			function = "gpio";
			drive-strength = <2>;
			bias-pull-down;
		};

		en-pins {
			pins = "gpio62";
			function = "gpio";
			drive-strength = <2>;
			bias-pull-up;
		};

		fw-pins {
			pins = "gpio86";
			function = "gpio";
			drive-strength = <2>;
			bias-disable;
		};

		clkreq-pins {
			pins = "gpio63";
			function = "gpio";
			drive-strength = <2>;
			bias-pull-up;
		};
	};

	pcie0_default_state: pcie0-default-state {
		perst-pins {
			pins = "gpio94";
			function = "gpio";
			drive-strength = <2>;
			bias-pull-down;
		};

		clkreq-pins {
			pins = "gpio95";
			function = "pcie0_clkreqn";
			drive-strength = <2>;
			bias-pull-up;
		};

		wake-pins {
			pins = "gpio96";
			function = "gpio";
			drive-strength = <2>;
			bias-pull-up;
		};
	};

	qup_spi2_default: qup-spi2-default-state {
		pins = "gpio12", "gpio13", "gpio14", "gpio15";
		function = "qup2";
		drive-strength = <6>;
		bias-disable;
	};

	qup_spi11_default: qup-spi11-default-state {
		pins = "gpio48", "gpio49", "gpio50", "gpio51";
		function = "qup11";
		drive-strength = <6>;
		bias-disable;
	};

	qup_uart18_bt: qup-uart18-bt-state {
		cts-pins {
			pins = "gpio68";
			function = "qup18";
			drive-strength = <2>;
			bias-disable;
		};

		rts-pins {
			pins = "gpio69";
			function = "qup18";
			drive-strength = <2>;
			bias-pull-down;
		};

		tx-pins {
			pins = "gpio70";
			function = "qup18";
			drive-strength = <2>;
			bias-pull-up;
		};

		rx-pins {
			pins = "gpio71";
			function = "qup18";
			drive-strength = <2>;
			bias-disable;
		};
	};

	sde_dsi_active: sde-dsi-active-state {
		pins = "gpio24";
		function = "gpio";
		drive-strength = <8>;
		bias-disable;
	};

	sde_dsi_sleep: sde-dsi-sleep-state {
		pins = "gpio24";
		function = "gpio";
		drive-strength = <2>;
		bias-pull-down;
	};

	sde_te_active: sde-te-active-state {
		pins = "gpio82";
		function = "mdp_vsync";
		drive-strength = <2>;
		bias-pull-down;
	};

	sde_te_sleep: sde-te-sleep-state {
		pins = "gpio82";
		function = "mdp_vsync";
		drive-strength = <2>;
		bias-pull-down;
	};

	spksw_default: spksw-default-state {
		pins = "gpio35";
		function = "gpio";
		drive-strength = <2>;
		bias-disable;
		output-low;
	};

	tert_tdm_active: tert-tdm-active-state {
		sck-pins {
			pins = "gpio120";
			function = "mi2s2_sck";
			drive-strength = <8>;
			bias-disable;
			output-high;
		};

		din-pins {
			pins = "gpio121";
			function = "mi2s2_data0";
			drive-strength = <8>;
			bias-disable;
		};

		ws-pins {
			pins = "gpio122";
			function = "mi2s2_ws";
			drive-strength = <8>;
			bias-disable;
			output-high;
		};

		dout-pins {
			pins = "gpio124";
			function = "mi2s2_data1";
			drive-strength = <8>;
			bias-disable;
		};
	};

	ts_active: ts-active-state {
		pins = "gpio22", "gpio23";
		function = "gpio";
		drive-strength = <8>;
		bias-pull-up;
	};

	pm8008i_int_default: pm8008i-int-default-state {
		pins = "gpio32";
		function = "gpio";
		drive-strength = <2>;
		bias-pull-down;
	};

	pm8008i_reset_default: pm8008i-reset-default-state {
		pins = "gpio33";
		function = "gpio";
		drive-strength = <2>;
		bias-disable;
	};

	cam_wide_reset_default: cam-wide-reset-default-state {
		pins = "gpio16";
		function = "gpio";
		drive-strength = <2>;
		bias-disable;
	};

	cam_front_reset_default: cam-front-reset-default-state {
		pins = "gpio17";
		function = "gpio";
		drive-strength = <2>;
		bias-disable;
	};

	cam_tele_reset_default: cam-tele-reset-default-state {
		pins = "gpio106";
		function = "gpio";
		drive-strength = <2>;
		bias-disable;
	};

	cam_ultra_reset_default: cam-ultra-reset-default-state {
		pins = "gpio117";
		function = "gpio";
		drive-strength = <2>;
		bias-disable;
	};

	wcd938x_reset_default: wcd938x-reset-default-state {
		pins = "gpio88";
		function = "gpio";
		drive-strength = <16>;
		output-high;
	};

	wlan_en_state: wlan-en-state {
		pins = "gpio64";
		function = "gpio";
		drive-strength = <16>;
		output-low;
		bias-pull-down;
	};
};

&txmacro {
	status = "okay";
};

&uart18 {
	pinctrl-0 = <&qup_uart18_bt>;
	pinctrl-names = "default";
	status = "okay";

	bluetooth {
		compatible = "qcom,wcn6855-bt";

		vddrfacmn-supply = <&vreg_pmu_rfa_cmn>;
		vddaon-supply = <&vreg_pmu_aon_0p8>;
		vddwlcx-supply = <&vreg_pmu_wlcx_0p8>;
		vddwlmx-supply = <&vreg_pmu_wlmx_0p8>;
		vddbtcmx-supply = <&vreg_pmu_btcmx_0p8>;
		vddrfa0p8-supply = <&vreg_pmu_rfa_0p8>;
		vddrfa1p2-supply = <&vreg_pmu_rfa_1p2>;
		vddrfa1p7-supply = <&vreg_pmu_rfa_1p7>;

		max-speed = <3000000>;
	};
};

&ufs_mem_hc {
	reset-gpios = <&tlmm 203 GPIO_ACTIVE_LOW>;
	vcc-supply = <&pm8350_l7>;
	vcc-max-microamp = <800000>;
	vccq-supply = <&pm8350_l9>;
	vccq-max-microamp = <900000>;
	status = "okay";
};

&ufs_mem_phy {
	vdda-phy-supply = <&pm8350_l5>;
	vdda-pll-supply = <&pm8350_l6>;
	status = "okay";
};

&usb_1 {
	qcom,select-utmi-as-pipe-clk;
	dr_mode = "otg";
	usb-role-switch;
	maximum-speed = "high-speed";
	phys = <&usb_1_hsphy>;
	phy-names = "usb2-phy";
	status = "okay";
};

&usb_1_dwc3_hs {
	remote-endpoint = <&pmic_glink_hs_in>;
};

&usb_1_dwc3_ss {
	/delete-property/ remote-endpoint;
};

&usb_1_hsphy {
	vdda-pll-supply = <&pm8350_l5>;
	vdda18-supply = <&pm8350c_l1>;
	vdda33-supply = <&pm8350_l2>;
	qcom,hs-disconnect-bp = <2156>;
	qcom,squelch-detector-bp = <1590>;
	qcom,hs-amplitude-bp = <2000>;
	qcom,pre-emphasis-duration-bp = <20000>;
	qcom,pre-emphasis-amplitude-bp = <40000>;
	qcom,hs-rise-fall-time-bp = <5430>;
	qcom,hs-crossover-voltage-microvolt = <(-31000)>;
	qcom,hs-output-impedance-micro-ohms = <6100000>;
	status = "okay";
};

&usb_1_qmpphy_usb_ss_in {
	/delete-property/ remote-endpoint;
};

&vamacro {
	status = "okay";
};
